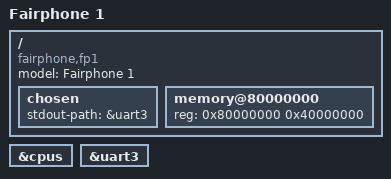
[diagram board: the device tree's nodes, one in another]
/dts-v1/;
#include "mt6589.dtsi"
/ {
	model = "Fairphone 1";
	compatible = "fairphone,fp1", "mediatek,mt6589";
	chosen {
		stdout-path = &uart3;
	};
	memory@80000000 {
		device_type = "memory";
		reg = <0x80000000 0x40000000>;
	};
};
&cpus {
	/delete-property/ enable-method;
};
&uart3 {
	status = "okay";
};
